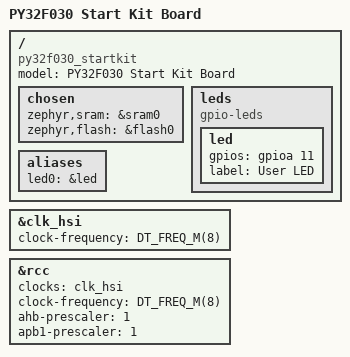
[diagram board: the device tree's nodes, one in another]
/*
 * Copyright (c) 2019 Antony Pavlov <antonynpavlov@gmail.com>
 *
 * SPDX-License-Identifier: Apache-2.0
 */

/dts-v1/;
#include <puya/f0/py32f030X4.dtsi>

/ {
	model = "PY32F030 Start Kit Board";
	compatible = "py32f030_startkit";

	chosen {
		zephyr,sram = &sram0;
		zephyr,flash = &flash0;
	};

	leds {
		compatible = "gpio-leds";
		led: led {
			gpios = <&gpioa 11 GPIO_ACTIVE_HIGH>;
			label = "User LED";
		};
	};

	aliases {
		led0 = &led;
	};
};

&clk_hsi {
	clock-frequency = <DT_FREQ_M(8)>;
	status = "okay";
};

&rcc {
	clocks = <&clk_hsi>;
	clock-frequency = <DT_FREQ_M(8)>;
	ahb-prescaler = <1>;
	apb1-prescaler = <1>;
};
